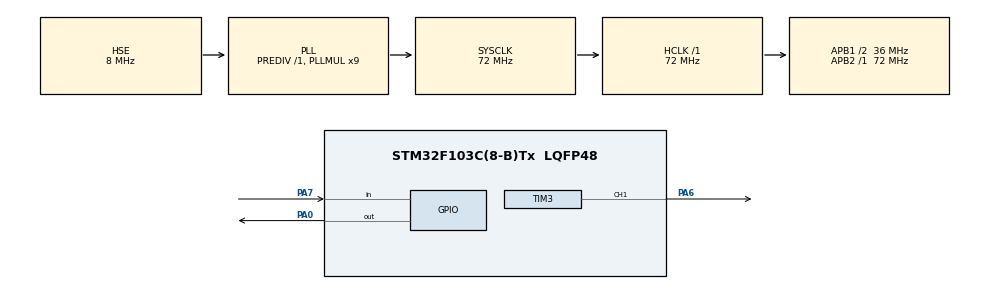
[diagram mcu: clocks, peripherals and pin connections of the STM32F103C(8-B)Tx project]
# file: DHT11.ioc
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Mcu.Family=STM32F1
Mcu.Name=STM32F103C(8-B)Tx
Mcu.Package=LQFP48
NVIC.PriorityGroup=NVIC_PRIORITYGROUP_4
NVIC.TIM3_IRQn=true\:2\:0\:true\:false\:true\:true\:true\:true
PA0-WKUP.Signal=GPIO_Output
PA13.Mode=Serial_Wire
PA13.Signal=SYS_JTMS-SWDIO
PA14.Mode=Serial_Wire
PA14.Signal=SYS_JTCK-SWCLK
PA6.Signal=S_TIM3_CH1
PA7.Signal=GPIO_Input
PD0-OSC_IN.Mode=HSE-External-Oscillator
PD0-OSC_IN.Signal=RCC_OSC_IN
PD1-OSC_OUT.Mode=HSE-External-Oscillator
PD1-OSC_OUT.Signal=RCC_OSC_OUT
ProjectManager.HeapSize=0x200
ProjectManager.StackSize=0x400
ProjectManager.TargetToolchain=MDK-ARM V5.32
RCC.AHBFreq_Value=72000000
RCC.APB1CLKDivider=RCC_HCLK_DIV2
RCC.APB1Freq_Value=36000000
RCC.APB1TimFreq_Value=72000000
RCC.APB2Freq_Value=72000000
RCC.APB2TimFreq_Value=72000000
RCC.HCLKFreq_Value=72000000
RCC.PLLMUL=RCC_PLL_MUL9
RCC.PLLSourceVirtual=RCC_PLLSOURCE_HSE
RCC.SYSCLKFreq_VALUE=72000000
RCC.SYSCLKSource=RCC_SYSCLKSOURCE_PLLCLK
RCC.USBFreq_Value=72000000
SH.S_TIM3_CH1.0=TIM3_CH1,PWM Generation1 CH1
TIM2.Period=65535
TIM2.Prescaler=71
TIM3.Channel-PWM\ Generation1\ CH1=TIM_CHANNEL_1
TIM3.Period=999
TIM3.Prescaler=71
VP_TIM2_VS_ClockSourceINT.Mode=Internal
VP_TIM3_VS_ClockSourceINT.Mode=Internal
board=custom

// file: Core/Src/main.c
/* USER CODE BEGIN Header */
/**
  ******************************************************************************
  * @file           : main.c
  * @brief          : Main program body
  ******************************************************************************
  * @attention
  *
  * Copyright (c) 2026 STMicroelectronics.
  * All rights reserved.
  *
  * This software is licensed under terms that can be found in the LICENSE file
  * in the root directory of this software component.
  * If no LICENSE file comes with this software, it is provided AS-IS.
  *
  ******************************************************************************
  */
/* USER CODE END Header */
#include "main.h"

TIM_HandleTypeDef htim2;
TIM_HandleTypeDef htim3;

void SystemClock_Config(void);
static void MX_GPIO_Init(void);
static void MX_TIM2_Init(void);
static void MX_TIM3_Init(void);

/* USER CODE BEGIN 0 */
#define DHT11_PORT GPIOA
#define DHT11_PIN  GPIO_PIN_7

uint8_t temperature = 0;
uint8_t humidity = 0;

void delay_us(uint16_t us) {
    __HAL_TIM_SET_COUNTER(&htim2, 0);
    while (__HAL_TIM_GET_COUNTER(&htim2) < us);
}

void Set_Pin_Output(void) {
    GPIO_InitTypeDef GPIO_InitStruct = {0};
    GPIO_InitStruct.Pin = DHT11_PIN;
    GPIO_InitStruct.Mode = GPIO_MODE_OUTPUT_PP;
    GPIO_InitStruct.Speed = GPIO_SPEED_FREQ_LOW;
    HAL_GPIO_Init(DHT11_PORT, &GPIO_InitStruct);
}

void Set_Pin_Input(void) {
    GPIO_InitTypeDef GPIO_InitStruct = {0};
    GPIO_InitStruct.Pin = DHT11_PIN;
    GPIO_InitStruct.Mode = GPIO_MODE_INPUT;
    GPIO_InitStruct.Pull = GPIO_PULLUP;
    HAL_GPIO_Init(DHT11_PORT, &GPIO_InitStruct);
}

uint8_t Wait_DHT11(GPIO_PinState state, uint16_t timeout_us) {
    __HAL_TIM_SET_COUNTER(&htim2, 0);
    while (HAL_GPIO_ReadPin(DHT11_PORT, DHT11_PIN) != state) {
        if (__HAL_TIM_GET_COUNTER(&htim2) > timeout_us) return 0;
    }
    return 1;
}

uint8_t DHT11_Read_Byte(void) {
    uint8_t result = 0;
    for (int i = 0; i < 8; i++) {
        if (!Wait_DHT11(GPIO_PIN_SET, 100)) return 0;

        __HAL_TIM_SET_COUNTER(&htim2, 0);

        if (!Wait_DHT11(GPIO_PIN_RESET, 100)) return 0;

        uint16_t duration = __HAL_TIM_GET_COUNTER(&htim2);

        result <<= 1;
        if (duration > 40) {
            result |= 1;
        }
    }
    return result;
}

uint8_t DHT11_Read(uint8_t *temp, uint8_t *hum) {
    uint8_t data[5] = {0};

    Set_Pin_Output();
    HAL_GPIO_WritePin(DHT11_PORT, DHT11_PIN, GPIO_PIN_RESET);
    HAL_Delay(18);
    HAL_GPIO_WritePin(DHT11_PORT, DHT11_PIN, GPIO_PIN_SET);
    delay_us(30);
    Set_Pin_Input();

    __disable_irq();

    if (!Wait_DHT11(GPIO_PIN_RESET, 90)) {
			__enable_irq(); return 0;
		}
    if (!Wait_DHT11(GPIO_PIN_SET, 90))   {
			__enable_irq(); return 0;
		}
    if (!Wait_DHT11(GPIO_PIN_RESET, 90)) {
			__enable_irq(); return 0;
		}

    for (int i = 0; i < 5; i++) {
        data[i] = DHT11_Read_Byte();
    }

    __enable_irq();

    if (data[4] == (data[0] + data[1] + data[2] + data[3])) {
        *hum  = data[0];
        *temp = data[2];
        return 1;
    }

    return 0;
}

volatile  uint8_t flag = 0;
volatile  uint16_t count = 0;

void HAL_TIM_PeriodElapsedCallback(TIM_HandleTypeDef *htim)
{
    if (htim->Instance == TIM3)
    {
			count ++;
			if(count >= 2000){
				flag = 1;
				count = 0;
			}

    }
}
/* USER CODE END 0 */

int main(void)
{

  /* MCU Configuration--------------------------------------------------------*/

  /* Reset of all peripherals, Initializes the Flash interface and the Systick. */
  HAL_Init();

  /* Configure the system clock */
  SystemClock_Config();

  /* Initialize all configured peripherals */
  MX_GPIO_Init();
  MX_TIM2_Init();
  MX_TIM3_Init();
  /* USER CODE BEGIN 2 */
	HAL_TIM_Base_Start(&htim2);
	HAL_TIM_Base_Start_IT(&htim3);
	HAL_TIM_PWM_Start(&htim3, TIM_CHANNEL_1);
  /* USER CODE END 2 */

  /* Infinite loop */
  while (1)
  {

    /* USER CODE BEGIN 3 */
		//DHT11_Read(&temperature, &humidity);
    //HAL_Delay(2000);
		if(flag) {
			HAL_GPIO_TogglePin(GPIOA, GPIO_PIN_0);
			flag = 0;
		}

  /* USER CODE END 3 */
	}
}

void SystemClock_Config(void)
{
  RCC_OscInitTypeDef RCC_OscInitStruct = {0};
  RCC_ClkInitTypeDef RCC_ClkInitStruct = {0};

  /** Initializes the RCC Oscillators according to the specified parameters
  * in the RCC_OscInitTypeDef structure.
  */
  RCC_OscInitStruct.OscillatorType = RCC_OSCILLATORTYPE_HSE;
  RCC_OscInitStruct.HSEState = RCC_HSE_ON;
  RCC_OscInitStruct.HSEPredivValue = RCC_HSE_PREDIV_DIV1;
  RCC_OscInitStruct.HSIState = RCC_HSI_ON;
  RCC_OscInitStruct.PLL.PLLState = RCC_PLL_ON;
  RCC_OscInitStruct.PLL.PLLSource = RCC_PLLSOURCE_HSE;
  RCC_OscInitStruct.PLL.PLLMUL = RCC_PLL_MUL9;
  if (HAL_RCC_OscConfig(&RCC_OscInitStruct) != HAL_OK)
  {
    Error_Handler();
  }

  /** Initializes the CPU, AHB and APB buses clocks
  */
  RCC_ClkInitStruct.ClockType = RCC_CLOCKTYPE_HCLK|RCC_CLOCKTYPE_SYSCLK
                              |RCC_CLOCKTYPE_PCLK1|RCC_CLOCKTYPE_PCLK2;
  RCC_ClkInitStruct.SYSCLKSource = RCC_SYSCLKSOURCE_PLLCLK;
  RCC_ClkInitStruct.AHBCLKDivider = RCC_SYSCLK_DIV1;
  RCC_ClkInitStruct.APB1CLKDivider = RCC_HCLK_DIV2;
  RCC_ClkInitStruct.APB2CLKDivider = RCC_HCLK_DIV1;

  if (HAL_RCC_ClockConfig(&RCC_ClkInitStruct, FLASH_LATENCY_2) != HAL_OK)
  {
    Error_Handler();
  }
}

static void MX_TIM2_Init(void)
{

  TIM_ClockConfigTypeDef sClockSourceConfig = {0};
  TIM_MasterConfigTypeDef sMasterConfig = {0};

  htim2.Instance = TIM2;
  htim2.Init.Prescaler = 71;
  htim2.Init.CounterMode = TIM_COUNTERMODE_UP;
  htim2.Init.Period = 65535;
  htim2.Init.ClockDivision = TIM_CLOCKDIVISION_DIV1;
  htim2.Init.AutoReloadPreload = TIM_AUTORELOAD_PRELOAD_DISABLE;
  if (HAL_TIM_Base_Init(&htim2) != HAL_OK)
  {
    Error_Handler();
  }
  sClockSourceConfig.ClockSource = TIM_CLOCKSOURCE_INTERNAL;
  if (HAL_TIM_ConfigClockSource(&htim2, &sClockSourceConfig) != HAL_OK)
  {
    Error_Handler();
  }
  sMasterConfig.MasterOutputTrigger = TIM_TRGO_RESET;
  sMasterConfig.MasterSlaveMode = TIM_MASTERSLAVEMODE_DISABLE;
  if (HAL_TIMEx_MasterConfigSynchronization(&htim2, &sMasterConfig) != HAL_OK)
  {
    Error_Handler();
  }

}

static void MX_TIM3_Init(void)
{

  TIM_ClockConfigTypeDef sClockSourceConfig = {0};
  TIM_MasterConfigTypeDef sMasterConfig = {0};
  TIM_OC_InitTypeDef sConfigOC = {0};

  htim3.Instance = TIM3;
  htim3.Init.Prescaler = 71;
  htim3.Init.CounterMode = TIM_COUNTERMODE_UP;
  htim3.Init.Period = 999;
  htim3.Init.ClockDivision = TIM_CLOCKDIVISION_DIV1;
  htim3.Init.AutoReloadPreload = TIM_AUTORELOAD_PRELOAD_DISABLE;
  if (HAL_TIM_Base_Init(&htim3) != HAL_OK)
  {
    Error_Handler();
  }
  sClockSourceConfig.ClockSource = TIM_CLOCKSOURCE_INTERNAL;
  if (HAL_TIM_ConfigClockSource(&htim3, &sClockSourceConfig) != HAL_OK)
  {
    Error_Handler();
  }
  if (HAL_TIM_PWM_Init(&htim3) != HAL_OK)
  {
    Error_Handler();
  }
  sMasterConfig.MasterOutputTrigger = TIM_TRGO_RESET;
  sMasterConfig.MasterSlaveMode = TIM_MASTERSLAVEMODE_DISABLE;
  if (HAL_TIMEx_MasterConfigSynchronization(&htim3, &sMasterConfig) != HAL_OK)
  {
    Error_Handler();
  }
  sConfigOC.OCMode = TIM_OCMODE_PWM1;
  sConfigOC.Pulse = 0;
  sConfigOC.OCPolarity = TIM_OCPOLARITY_HIGH;
  sConfigOC.OCFastMode = TIM_OCFAST_DISABLE;
  if (HAL_TIM_PWM_ConfigChannel(&htim3, &sConfigOC, TIM_CHANNEL_1) != HAL_OK)
  {
    Error_Handler();
  }
  HAL_TIM_MspPostInit(&htim3);

}

static void MX_GPIO_Init(void)
{
  GPIO_InitTypeDef GPIO_InitStruct = {0};

  /* GPIO Ports Clock Enable */
  __HAL_RCC_GPIOD_CLK_ENABLE();
  __HAL_RCC_GPIOA_CLK_ENABLE();

  /*Configure GPIO pin Output Level */
  HAL_GPIO_WritePin(GPIOA, GPIO_PIN_0, GPIO_PIN_RESET);

  /*Configure GPIO pin : PA0 */
  GPIO_InitStruct.Pin = GPIO_PIN_0;
  GPIO_InitStruct.Mode = GPIO_MODE_OUTPUT_PP;
  GPIO_InitStruct.Pull = GPIO_NOPULL;
  GPIO_InitStruct.Speed = GPIO_SPEED_FREQ_LOW;
  HAL_GPIO_Init(GPIOA, &GPIO_InitStruct);

  /*Configure GPIO pin : PA7 */
  GPIO_InitStruct.Pin = GPIO_PIN_7;
  GPIO_InitStruct.Mode = GPIO_MODE_INPUT;
  GPIO_InitStruct.Pull = GPIO_NOPULL;
  HAL_GPIO_Init(GPIOA, &GPIO_InitStruct);

}

void Error_Handler(void)
{
  __disable_irq();
  while (1)
  {
  }
}
